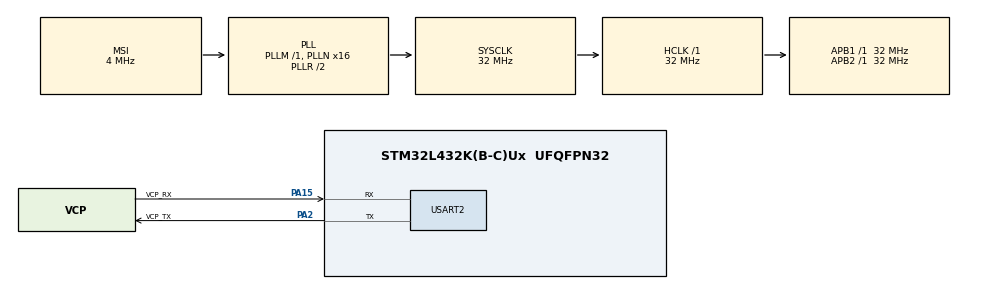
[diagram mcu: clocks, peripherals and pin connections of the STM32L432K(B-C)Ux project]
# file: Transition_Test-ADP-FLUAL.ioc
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Mcu.Family=STM32L4
Mcu.Name=STM32L432K(B-C)Ux
Mcu.Package=UFQFPN32
NVIC.PriorityGroup=NVIC_PRIORITYGROUP_4
NVIC.USART2_IRQn=true\:0\:0\:false\:false\:true\:true\:true
PA0.GPIO_Label=MCO [High speed clock in]
PA0.Mode=HSE-External-Clock-Source-for-LittleOrca
PA0.Signal=RCC_CK_IN
PA13\ (JTMS-SWDIO).GPIO_Label=SWDIO
PA13\ (JTMS-SWDIO).Mode=Serial_Wire
PA13\ (JTMS-SWDIO).Signal=SYS_JTMS-SWDIO
PA14\ (JTCK-SWCLK).GPIO_Label=SWCLK
PA14\ (JTCK-SWCLK).Mode=Serial_Wire
PA14\ (JTCK-SWCLK).Signal=SYS_JTCK-SWCLK
PA15\ (JTDI).GPIO_Label=VCP_RX
PA15\ (JTDI).Mode=Asynchronous
PA15\ (JTDI).Signal=USART2_RX
PA2.GPIO_Label=VCP_TX
PA2.Mode=Asynchronous
PA2.Signal=USART2_TX
PC14-OSC32_IN\ (PC14).Mode=LSE-External-Oscillator
PC14-OSC32_IN\ (PC14).Signal=RCC_OSC32_IN
PC15-OSC32_OUT\ (PC15).Mode=LSE-External-Oscillator
PC15-OSC32_OUT\ (PC15).Signal=RCC_OSC32_OUT
ProjectManager.HeapSize=0x200
ProjectManager.StackSize=0x400
ProjectManager.TargetToolchain=STM32CubeIDE
RCC.AHBFreq_Value=32000000
RCC.APB1Freq_Value=32000000
RCC.APB1TimFreq_Value=32000000
RCC.APB2Freq_Value=32000000
RCC.APB2TimFreq_Value=32000000
RCC.CortexFreq_Value=32000000
RCC.HCLKFreq_Value=32000000
RCC.HSE_VALUE=8000000
RCC.HSI16_VALUE=16000000
RCC.HSI48_VALUE=48000000
RCC.HSI_VALUE=16000000
RCC.MSI_VALUE=4000000
RCC.PLLMUL=RCC_PLLMUL_4
RCC.PLLN=16
RCC.SYSCLKFreq_VALUE=32000000
RCC.SYSCLKSource=RCC_SYSCLKSOURCE_PLLCLK
RCC.VCOOutputFreq_Value=64000000
USART2.VirtualMode-Asynchronous=VM_ASYNC
board=NUCLEO-L432KC

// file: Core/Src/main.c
/* USER CODE BEGIN Header */
/**
 ******************************************************************************
 * @file           : main.c
 * @brief          : Main program body
 ******************************************************************************
 * @attention
 *
 * <h2><center>&copy; Copyright (c) 2021 STMicroelectronics.
 * All rights reserved.</center></h2>
 *
 * This software component is licensed by ST under BSD 3-Clause license,
 * the "License"; You may not use this file except in compliance with the
 * License. You may obtain a copy of the License at:
 *                        opensource.org/licenses/BSD-3-Clause
 *
 ******************************************************************************
 */
/* USER CODE END Header */
#include "main.h"

/* USER CODE BEGIN Includes */
#include "sm_adp-flual.h"
#include "stdbool.h"
#include "string.h"

/* USER CODE END Includes */

/* USER CODE BEGIN PD */
#define SUCCESS_TEXT (const uint8_t*) "\033[0;30;42mTest Success!\033[0;39;49m\n\r"
#define FAIL_TEXT	 (const uint8_t*) "\033[0;37;41mTest Fail!\033[0;39;49m\n\r"

#define SETUP_EXECUTED			0x00000001
#define NEW_FILE_EXECUTED 		0x00000002
#define BLINK_RED_LED			0x00000004
#define SEEK_WIFI_NETWORK		0x00000008
#define PLAY_LAST_SOUND			0x00000010
#define CLOSE_FILE_RECORDED		0x00000020
#define START_SEND				0x00000040
#define FINISH_SEND				0x00000080
#define CONNECTION_FAIL_ALERT	0x00000100
#define SEND_MESSAGE_ALERT  	0x00000200
#define REBOOT_CAPTURE_FUNCTION 0x00000400

/* USER CODE END PD */

UART_HandleTypeDef huart2;

/* USER CODE BEGIN PV */
/*Events status variables
 *
 * */

bool TurnOnEvent = false;
bool VoiceCommandEvent = false;
bool TimerOutEvent = false;
bool ConnectionEvent = false;
bool SendStatusEvent = false;
bool PlayStatusEvent = false;
/*Actions status variables
 *
 * */
voiceCommandEnum_t voiceCommand = VC_INVALID;
connectionStatusEnum_t connectionStatus = CONNECTION_STATUS_OFF;
sendStatusEnum_t sendStatus = SEND_OFF;
playStatusEvent_t playStatus = STOP_PLAY;
uint32_t executed_routines = 0;

/* USER CODE END PV */

void SystemClock_Config(void);
static void MX_GPIO_Init(void);
static void MX_USART2_UART_Init(void);

/* USER CODE BEGIN 0 */
void send_Serial(const uint8_t * text){
	HAL_UART_Transmit(&huart2, (uint8_t *)text, strlen((const char *)text), 1000);
}

/*****************************************************************************
 * MOC for Actions application
 *
 */
void setup(void){
	executed_routines |= SETUP_EXECUTED;
}

void newFileExecuted(void){
	executed_routines |= NEW_FILE_EXECUTED;
}

void blinkRedLed(void){
	executed_routines |= BLINK_RED_LED;
}

void seekWifiNetwork(void){
	executed_routines |= SEEK_WIFI_NETWORK;
}

void playLastSound(void){
	executed_routines |= PLAY_LAST_SOUND;
}

void stopRecord(void){
	executed_routines |= CLOSE_FILE_RECORDED;
}

void startSend(void){
	executed_routines |= START_SEND;
}

void connectionFailAlert(void){
	executed_routines |= CONNECTION_FAIL_ALERT;
}

void sendMessageAlert(void){
	executed_routines |= SEND_MESSAGE_ALERT;
}

void rebootCaptureFunction(void){
	executed_routines |= REBOOT_CAPTURE_FUNCTION;
}
/*****************************************************************************
 * Mocs for Events application
 *
 */
void generateTurnOnEvent(void){
	TurnOnEvent = true;
}

bool getTurnOnEvent(void){
	bool retVal = TurnOnEvent;

	TurnOnEvent = false;
	return retVal;
}

void generateVoiceCommandEvent(voiceCommandEnum_t value){
	voiceCommand = value;
	VoiceCommandEvent = true;
}

bool getVoiceCommandEvent(voiceCommandEnum_t *trigger){
	bool retVal = VoiceCommandEvent;
	*trigger = voiceCommand;
	VoiceCommandEvent = false;
	voiceCommand = VC_INVALID;
	return retVal;
}

void generateTimerOutEvent(void){
	TimerOutEvent = true;
}

bool getTimerOutEvent(void){
	bool retVal = TimerOutEvent;
	TimerOutEvent = false;
	return retVal;
}

void generateConnectionEvent(connectionStatusEnum_t value){
	connectionStatus = value;
	ConnectionEvent = true;
}

bool getConnectionEvent(connectionStatusEnum_t *trigger){
	bool retVal = ConnectionEvent;
	*trigger = connectionStatus;
	ConnectionEvent = false;
	connectionStatus = CONNECTION_STATUS_OFF;
	return retVal;
}

void generateSendStatusEvent(sendStatusEnum_t value){
	sendStatus = value;
	SendStatusEvent = true;
}

bool getSendStatusEvent(sendStatusEnum_t *trigger){
	bool retVal = SendStatusEvent;
	*trigger = sendStatus;
	SendStatusEvent = false;
	sendStatus = SEND_OFF;
	return retVal;
}

void generatePlayStatusEvent(playStatusEvent_t value){
	playStatus = value;
	PlayStatusEvent = true;
}

bool getPlayStatusEvent(playStatusEvent_t *trigger){
	bool retVal = PlayStatusEvent;
	*trigger = playStatus;
	PlayStatusEvent = false;
	playStatus = STOP_PLAY;
	return retVal;
}

/* USER CODE END 0 */

int main(void)
{

	/* MCU Configuration--------------------------------------------------------*/

	/* Reset of all peripherals, Initializes the Flash interface and the Systick. */
	HAL_Init();

	/* Configure the system clock */
	SystemClock_Config();

	/* Initialize all configured peripherals */
	MX_GPIO_Init();
	MX_USART2_UART_Init();

	/* USER CODE BEGIN 2 */
	/*
	 * Clear terminal prompt.
	 */
	send_Serial((const uint8_t *)"\033c");

	/*
	 * 1o teste de transição quando sai do Shutdown e configura o ambiente para READY.
	 *
	 * */
	send_Serial((const uint8_t *)"Transition Test1: ");
	executed_routines = 0;
	adpflual_setState(SHUTDOWN);
	generateTurnOnEvent();
	adpflual_State_Machine();

	if(adpflual_getState()== SM_READY && executed_routines == (SETUP_EXECUTED)){
		//Sucesso no teste.
		send_Serial(SUCCESS_TEXT);
	}
	else {
		//Falha no teste.
		send_Serial(FAIL_TEXT);
	}

	/*
	 * 2o teste de transição quando sai do Ready e entra em Record_id para começar
	 * uma gravação de arquivo no cartão SD.
	 *
	 * */
	send_Serial((const uint8_t *)"Transition Test2: ");
	executed_routines = 0;
	adpflual_setState(SM_READY);
	generateVoiceCommandEvent(VC_RECORD_ID);
	adpflual_State_Machine();

	if(adpflual_getState()== SM_RECORD_ID && executed_routines == (NEW_FILE_EXECUTED)){
		//Sucesso no teste.
		send_Serial(SUCCESS_TEXT);
	}
	else {
		//Falha no teste.
		send_Serial(FAIL_TEXT);
	}

	/*
	 * 3o teste de transição quando sai do Ready e entra em Record_Fluency para começar
	 * uma gravação de arquivo no cartão SD.
	 *
	 * */
	send_Serial((const uint8_t *)"Transition Test3: ");
	executed_routines = 0;
	adpflual_setState(SM_READY);
	generateVoiceCommandEvent(VC_RECORD_FLUENCY);
	adpflual_State_Machine();

	if(adpflual_getState()== SM_RECORD_FLUENCY && executed_routines == (NEW_FILE_EXECUTED)){
		//Sucesso no teste.
		send_Serial(SUCCESS_TEXT);
	}
	else {
		//Falha no teste.
		send_Serial(FAIL_TEXT);
	}

	/*
	 * 4o teste de transição quando sai do Ready e entra em Hard_fault para começar
	 * uma gravação de arquivo no cartão SD.
	 *
	 * */
	send_Serial((const uint8_t *)"Transition Test4: ");
	executed_routines = 0;
	adpflual_setState(SM_READY);
	generateTimerOutEvent();
	adpflual_State_Machine();

	if(adpflual_getState()== SM_HARD_FAULT && executed_routines == (BLINK_RED_LED)){
		//Sucesso no teste.
		send_Serial(SUCCESS_TEXT);
	}
	else {
		//Falha no teste.
		send_Serial(FAIL_TEXT);
	}

	/*
	 * 5o teste de transição quando sai do Ready e entra em Connect para começar uma gravação
	 * do arquivo no cartão SD.
	 *
	 * */
	send_Serial((const uint8_t *)"Transition Test5: ");
	executed_routines = 0;
	adpflual_setState(SM_READY);
	generateVoiceCommandEvent(VC_SEND);
	adpflual_State_Machine();

	if(adpflual_getState()== SM_CONNECT && executed_routines == (SEEK_WIFI_NETWORK)){
		//Sucesso no teste.
		send_Serial(SUCCESS_TEXT);
	}
	else {
		//Falha no teste.
		send_Serial(FAIL_TEXT);
	}

	/*
	 * 6o teste de transição quando sai do Ready e entra em PLay para começar uma reprodução
	 * do arquivo no cartão SD.
	 *
	 * */
	send_Serial((const uint8_t *)"Transition Test6: ");
	executed_routines = 0;
	adpflual_setState(SM_READY);
	generateVoiceCommandEvent(VC_PLAY_RECORDED);
	adpflual_State_Machine();

	if(adpflual_getState()== SM_PLAY && executed_routines == (PLAY_LAST_SOUND)){
		//Sucesso no teste.
		send_Serial(SUCCESS_TEXT);
	}
	else {
		//Falha no teste.
		send_Serial(FAIL_TEXT);
	}
	/*
	 * 7o teste de transição quando sai do Record_ID e entra em Ready para finalizar a gravação
	 * do arquivo no cartão SD.
	 *
	 * */
	send_Serial((const uint8_t *)"Transition Test7: ");
	executed_routines = 0;
	adpflual_setState(SM_RECORD_ID);
	generateVoiceCommandEvent(VC_STOP_RECORD);
	adpflual_State_Machine();

	if(adpflual_getState()== SM_READY && executed_routines == (CLOSE_FILE_RECORDED)){
		//Sucesso no teste.
		send_Serial(SUCCESS_TEXT);
	}
	else {
		//Falha no teste.
		send_Serial(FAIL_TEXT);
	}
	/*
	 * 8o teste de transição quando sai do Record Fluency Sound
	 * e entra em Ready para finalizar a gravação de fluência no
	 * arquivo no cartão SD.
	 *
	 * */
	send_Serial((const uint8_t *)"Transition Test8: ");
	executed_routines = 0;
	adpflual_setState(SM_RECORD_FLUENCY);
	generateVoiceCommandEvent(VC_STOP_RECORD);
	adpflual_State_Machine();

	if(adpflual_getState()== SM_READY && executed_routines == (CLOSE_FILE_RECORDED)){
		//Sucesso no teste.
		send_Serial(SUCCESS_TEXT);
	}
	else {
		//Falha no teste.
		send_Serial(FAIL_TEXT);
	}
	/*
	 * 9o teste de transição quando sai do Connect e entra em SEND
	 * para enviar os arquivos de áudio para o servidor.
	 *
	 * */
	send_Serial((const uint8_t *)"Transition Test9: ");
	executed_routines = 0;
	adpflual_setState(SM_CONNECT);
	generateConnectionEvent(CONNECTION_STATUS_SUCCESS);
	adpflual_State_Machine();

	if(adpflual_getState()== SM_SEND && executed_routines == (START_SEND)){
		//Sucesso no teste.
		send_Serial(SUCCESS_TEXT);
	}
	else {
		//Falha no teste.
		send_Serial(FAIL_TEXT);
	}
	/*
	 * 10o teste de transição quando sai do Connect e volta para READY
	 * para enviar os arquivos de áudio para o servidor.
	 *
	 * */
	send_Serial((const uint8_t *)"Transition Test10: ");
	executed_routines = 0;
	adpflual_setState(SM_CONNECT);
	generateConnectionEvent(CONNECTION_STATUS_FAIL);
	adpflual_State_Machine();

	if(adpflual_getState()== SM_READY && executed_routines == (CONNECTION_FAIL_ALERT)){
		//Sucesso no teste.
		send_Serial(SUCCESS_TEXT);
	}
	else {
		//Falha no teste.
		send_Serial(FAIL_TEXT);
	}
	/*
	 * 11o teste de transição quando sai do SEND e volta para READY
	 * informando o sucesso do envio dos arquivos de áudio para o servidor.
	 *
	 * */
	send_Serial((const uint8_t *)"Transition Test11: ");
	executed_routines = 0;
	adpflual_setState(SM_SEND);
	generateSendStatusEvent(SEND_SUCCESS);
	adpflual_State_Machine();

	if(adpflual_getState()== SM_READY && executed_routines == (SEND_MESSAGE_ALERT)){
		//Sucesso no teste.
		send_Serial(SUCCESS_TEXT);
	}
	else {
		//Falha no teste.
		send_Serial(FAIL_TEXT);
	}

	/*
	 * 12o teste de transição quando sai do SEND e volta para READY
	 * informando a falha de envio dos arquivos de áudio para o servidor.
	 *
	 * */
	send_Serial((const uint8_t *)"Transition Test12: ");
	executed_routines = 0;
	adpflual_setState(SM_SEND);
	generateSendStatusEvent(SEND_FAIL);
	adpflual_State_Machine();

	if(adpflual_getState()== SM_READY && executed_routines == (SEND_MESSAGE_ALERT)){
		//Sucesso no teste.
		send_Serial(SUCCESS_TEXT);
	}
	else {
		//Falha no teste.
		send_Serial(FAIL_TEXT);
	}
	/*
	 * 13o teste de transição quando sai do PLAY e volta para READY
	 * finalizando a reprodução do áudio.
	 *
	 * */
	send_Serial((const uint8_t *)"Transition Test13: ");
	executed_routines = 0;
	adpflual_setState(SM_PLAY);
	generatePlayStatusEvent(STOP_PLAY);
	adpflual_State_Machine();

	if(adpflual_getState()== SM_READY && executed_routines == (REBOOT_CAPTURE_FUNCTION)){
		//Sucesso no teste.
		send_Serial(SUCCESS_TEXT);
	}
	else {
		//Falha no teste.
		send_Serial(FAIL_TEXT);
	}

	/* USER CODE END 2 */

	/* Infinite loop */
	while (1)
	{

		/* USER CODE BEGIN 3 */
	}
}

void SystemClock_Config(void)
{
	RCC_OscInitTypeDef RCC_OscInitStruct = {0};
	RCC_ClkInitTypeDef RCC_ClkInitStruct = {0};

	/** Configure the main internal regulator output voltage
	 */
	if (HAL_PWREx_ControlVoltageScaling(PWR_REGULATOR_VOLTAGE_SCALE1) != HAL_OK)
	{
		Error_Handler();
	}
	/** Configure LSE Drive Capability
	 */
	HAL_PWR_EnableBkUpAccess();
	__HAL_RCC_LSEDRIVE_CONFIG(RCC_LSEDRIVE_LOW);
	/** Initializes the RCC Oscillators according to the specified parameters
	 * in the RCC_OscInitTypeDef structure.
	 */
	RCC_OscInitStruct.OscillatorType = RCC_OSCILLATORTYPE_LSE|RCC_OSCILLATORTYPE_MSI;
	RCC_OscInitStruct.LSEState = RCC_LSE_ON;
	RCC_OscInitStruct.MSIState = RCC_MSI_ON;
	RCC_OscInitStruct.MSICalibrationValue = 0;
	RCC_OscInitStruct.MSIClockRange = RCC_MSIRANGE_6;
	RCC_OscInitStruct.PLL.PLLState = RCC_PLL_ON;
	RCC_OscInitStruct.PLL.PLLSource = RCC_PLLSOURCE_MSI;
	RCC_OscInitStruct.PLL.PLLM = 1;
	RCC_OscInitStruct.PLL.PLLN = 16;
	RCC_OscInitStruct.PLL.PLLP = RCC_PLLP_DIV7;
	RCC_OscInitStruct.PLL.PLLQ = RCC_PLLQ_DIV2;
	RCC_OscInitStruct.PLL.PLLR = RCC_PLLR_DIV2;
	if (HAL_RCC_OscConfig(&RCC_OscInitStruct) != HAL_OK)
	{
		Error_Handler();
	}
	/** Initializes the CPU, AHB and APB buses clocks
	 */
	RCC_ClkInitStruct.ClockType = RCC_CLOCKTYPE_HCLK|RCC_CLOCKTYPE_SYSCLK
			|RCC_CLOCKTYPE_PCLK1|RCC_CLOCKTYPE_PCLK2;
	RCC_ClkInitStruct.SYSCLKSource = RCC_SYSCLKSOURCE_PLLCLK;
	RCC_ClkInitStruct.AHBCLKDivider = RCC_SYSCLK_DIV1;
	RCC_ClkInitStruct.APB1CLKDivider = RCC_HCLK_DIV1;
	RCC_ClkInitStruct.APB2CLKDivider = RCC_HCLK_DIV1;

	if (HAL_RCC_ClockConfig(&RCC_ClkInitStruct, FLASH_LATENCY_1) != HAL_OK)
	{
		Error_Handler();
	}
	/** Enable MSI Auto calibration
	 */
	HAL_RCCEx_EnableMSIPLLMode();
}

static void MX_USART2_UART_Init(void)
{

	huart2.Instance = USART2;
	huart2.Init.BaudRate = 115200;
	huart2.Init.WordLength = UART_WORDLENGTH_8B;
	huart2.Init.StopBits = UART_STOPBITS_1;
	huart2.Init.Parity = UART_PARITY_NONE;
	huart2.Init.Mode = UART_MODE_TX_RX;
	huart2.Init.HwFlowCtl = UART_HWCONTROL_NONE;
	huart2.Init.OverSampling = UART_OVERSAMPLING_16;
	huart2.Init.OneBitSampling = UART_ONE_BIT_SAMPLE_DISABLE;
	huart2.AdvancedInit.AdvFeatureInit = UART_ADVFEATURE_NO_INIT;
	if (HAL_UART_Init(&huart2) != HAL_OK)
	{
		Error_Handler();
	}

}

static void MX_GPIO_Init(void)
{

	/* GPIO Ports Clock Enable */
	__HAL_RCC_GPIOC_CLK_ENABLE();
	__HAL_RCC_GPIOA_CLK_ENABLE();

}

void Error_Handler(void)
{
	__disable_irq();
	while (1)
	{
	}
}

/************************ (C) COPYRIGHT STMicroelectronics *****END OF FILE****/
